# FILTER register map
Vendor: Texas Instruments
Peripheral module from a debugger description file (folder ucd3138064A).
Registers are 32-bit, access not given, no defined reset value unless marked. A register's access mark holds for its fields unless they carry their own. Offsets are as the file gives them; lines under a group give offsets from that group; [hi:lo] are bit positions; {n}, {i} and the like mark numbered series; 'fields as' and 'values as' point back to an identical list; <NAME> marks a mode.

## FILTER
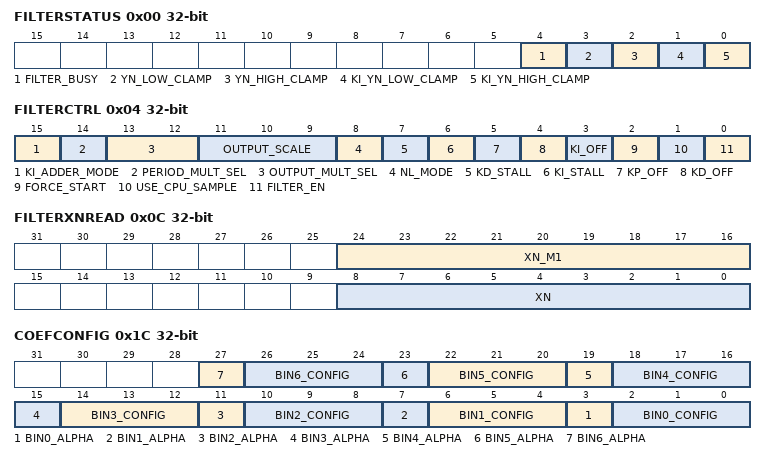
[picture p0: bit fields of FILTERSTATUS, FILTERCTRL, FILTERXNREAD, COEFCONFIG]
0x00 FILTERSTATUS
  [4] FILTER_BUSY ro — Filter Busy Indication
  [3] YN_LOW_CLAMP ro — Output Clamp Low Indication
  [2] YN_HIGH_CLAMP ro — Output Clamp High Indication
  [1] KI_YN_LOW_CLAMP ro — KI Feedback Clamp Low Indication
  [0] KI_YN_HIGH_CLAMP ro — KI Feedback Clamp High Indication
0x04 FILTERCTRL — Filter Control Register
  [15] KI_ADDER_MODE rw — KI Adder Mode Select
  [14] PERIOD_MULT_SEL rw — Period Multiplier Select
  [13:12] OUTPUT_MULT_SEL rw — Output Multiplicand Select
  [11:9] OUTPUT_SCALE rw — Output Scaling
  [8] NL_MODE rw — Selects Non-linear Mode
  [7] KD_STALL rw — Stalls KD Branch
  [6] KI_STALL rw — Stalls KI Branch
  [5] KP_OFF rw — Turns off KP Branch
  [4] KD_OFF rw — Turns off KD Branch
  [3] KI_OFF rw — Turns off KI Branch
  [2] FORCE_START rw — Software Filter Calculation
  [1] USE_CPU_SAMPLE rw
  [0] FILTER_EN rw — Filter Enable
0x08 CPUXN
  [8:0] CPU_SAMPLE rw
0x0C FILTERXNREAD
  [24:16] XN_M1 ro — XN_M1 Value
  [8:0] XN ro — XN Value
0x10 FILTERKIYNREAD
  [23:0] KI_YN ro — KI_YN Value
0x14 FILTERKDYNREAD
  [23:0] KD_YN ro — KD_YN Value
0x18 FILTERYNREAD
  [23:0] YN ro — YN Value
0x1C COEFCONFIG — Coefficient Configuration Register
  [4n+3] BIN{n}_ALPHA rw (n=0..6) — Bin{n} Alpha Configuration
  [4n+2:4n] BIN{n}_CONFIG rw (n=0..6) — Bin{n} Configuration
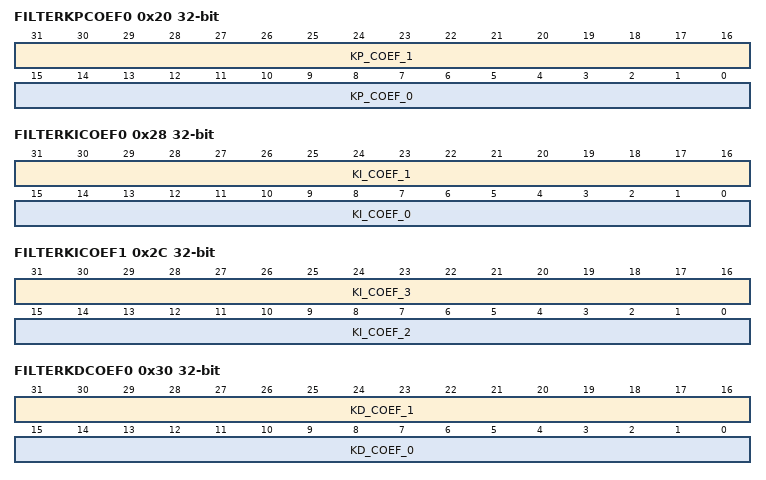
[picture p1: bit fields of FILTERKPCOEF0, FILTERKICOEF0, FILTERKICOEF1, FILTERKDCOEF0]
0x20 FILTERKPCOEF0 rw — Filter KP Coefficient 0 Register
  [31:16] KP_COEF_1 — KP Coefficient 1
  [15:0] KP_COEF_0 — KP Coefficient 0
0x24 FILTERKPCOEF1 — Filter KP Coefficient 1 Register
  [15:0] KP_COEF_2 rw — KP Coefficient 2
0x28 FILTERKICOEF0 rw — Filter KI Coefficient 0 Register
  [31:16] KI_COEF_1 — KI Coefficient 1
  [15:0] KI_COEF_0 — KI Coefficient 0
0x2C FILTERKICOEF1 rw — Filter KI Coefficient 1 Register
  [31:16] KI_COEF_3 — KI Coefficient 3
  [15:0] KI_COEF_2 — KI Coefficient 2
0x30 FILTERKDCOEF0 rw — Filter KD Coefficient 0 Register
  [31:16] KD_COEF_1 — KD Coefficient 1
  [15:0] KD_COEF_0 — KD Coefficient 0
0x34 FILTERKDCOEF1 — Filter KD Coefficient 1 Register
  [15:0] KD_COEF_2 rw — KD Coefficient 2
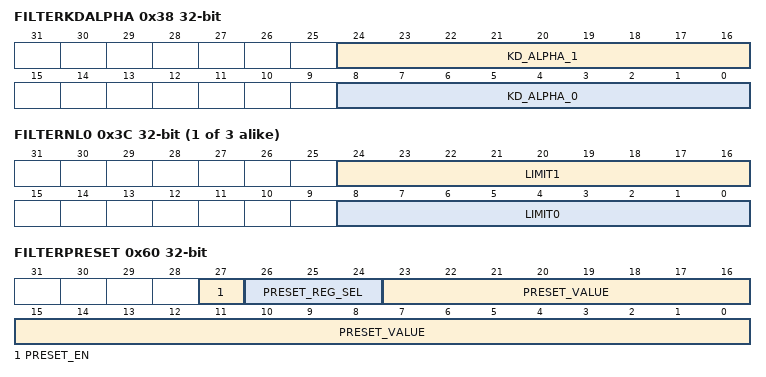
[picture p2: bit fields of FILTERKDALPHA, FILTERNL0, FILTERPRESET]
0x38 FILTERKDALPHA
  [24:16] KD_ALPHA_1 rw — KD Alpha 1 Value
  [8:0] KD_ALPHA_0 rw — KD Alpha 0 Value
{0x3C+4i} FILTERNL{i} (i=0..2) — Filter Non-Linear Limit {i} Register
  [24:16] LIMIT{2i+1} rw — Non-Linear Limit {2i+1} Value
  [8:0] LIMIT{2i} rw — Non-Linear Limit {2i} Value
0x48 FILTERKICLPHI — Filter KI Feedback Clamp High Register
  [23:0] KI_CLAMP_HIGH rw
0x4C FILTERKICLPLO — Filter KI Feedback Clamp Low Register
  [23:0] KI_CLAMP_LOW rw
0x50 FILTERYNCLPHI — Filter Yn Clamp High Register
  [23:0] YN_CLAMP_HIGH rw
0x54 FILTERYNCLPLO — Filter Yn Clamp Low Register
  [23:0] YN_CLAMP_LOW rw — YN Clamp High
0x58 FILTEROCLPHI — Filter Output Clamp High Register
  [17:0] OUTPUT_CLAMP_HIGH rw
0x5C FILTEROCLPLO — Filter Output Clamp Low Register
  [17:0] OUTPUT_CLAMP_LOW rw
0x60 FILTERPRESET
  [27] PRESET_EN rw — Filter Preset Enable
  [26:24] PRESET_REG_SEL rw — Filter Preset Select
  [23:0] PRESET_VALUE rw — Filter Preset Value
